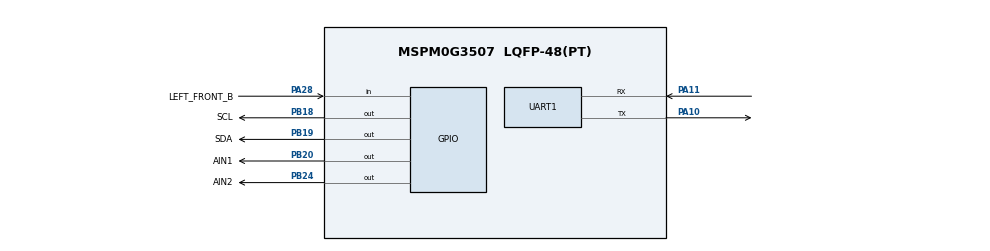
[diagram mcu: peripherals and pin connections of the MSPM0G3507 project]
/**
 * These arguments were used when this file was generated. They will be automatically applied on subsequent loads
 * via the GUI or CLI. Run CLI with '--help' for additional information on how to override these arguments.
 * @cliArgs --device "MSPM0G350X" --part "Default" --package "LQFP-48(PT)" --product "mspm0_sdk@2.10.00.04"
 * @v2CliArgs --device "MSPM0G3507" --package "LQFP-48(PT)" --product "mspm0_sdk@2.10.00.04"
 * @versions {"tool":"1.26.2+4477"}
 */

/**
 * Import the modules used in this configuration.
 */
const ADC12    = scripting.addModule("/ti/driverlib/ADC12", {}, false);
const ADC121   = ADC12.addInstance();
const CAPTURE  = scripting.addModule("/ti/driverlib/CAPTURE", {}, false);
const CAPTURE1 = CAPTURE.addInstance();
const CAPTURE2 = CAPTURE.addInstance();
const CAPTURE3 = CAPTURE.addInstance();
const CAPTURE4 = CAPTURE.addInstance();
const GPIO     = scripting.addModule("/ti/driverlib/GPIO", {}, false);
const GPIO1    = GPIO.addInstance();
const GPIO2    = GPIO.addInstance();
const GPIO3    = GPIO.addInstance();
const GPIO4    = GPIO.addInstance();
const PWM      = scripting.addModule("/ti/driverlib/PWM", {}, false);
const PWM1     = PWM.addInstance();
const SYSCTL   = scripting.addModule("/ti/driverlib/SYSCTL");
const TIMER    = scripting.addModule("/ti/driverlib/TIMER", {}, false);
const TIMER1   = TIMER.addInstance();
const UART     = scripting.addModule("/ti/driverlib/UART", {}, false);
const UART1    = UART.addInstance();

/**
 * Write custom configuration values to the imported modules.
 */
const divider9       = system.clockTree["UDIV"];
divider9.divideValue = 2;

const gate7  = system.clockTree["MFCLKGATE"];
gate7.enable = true;

const multiplier2         = system.clockTree["PLL_QDIV"];
multiplier2.multiplyValue = 4;

const mux4       = system.clockTree["EXHFMUX"];
mux4.inputSelect = "EXHFMUX_XTAL";

const mux8       = system.clockTree["HSCLKMUX"];
mux8.inputSelect = "HSCLKMUX_SYSPLL0";

const mux12       = system.clockTree["SYSPLLMUX"];
mux12.inputSelect = "zSYSPLLMUX_HFCLK";

const pinFunction4        = system.clockTree["HFXT"];
pinFunction4.inputFreq    = 40;
pinFunction4.enable       = true;
pinFunction4.HFCLKMonitor = true;
pinFunction4.HFXTStartup  = 10;

ADC121.repeatMode                        = true;
ADC121.sampClkDiv                        = "DL_ADC12_CLOCK_DIVIDE_8";
ADC121.adcMem0_name                      = "ADC_CH0";
ADC121.$name                             = "ADC_VOLTAGE";
ADC121.sampleTime0                       = "10 ms";
ADC121.enabledInterrupts                 = ["DL_ADC12_INTERRUPT_MEM0_RESULT_LOADED"];
ADC121.adcPin0Config.hideOutputInversion = scripting.forceWrite(false);
ADC121.adcPin0Config.$name               = "ti_driverlib_gpio_GPIOPinGeneric9";

const Board = scripting.addModule("/ti/driverlib/Board", {}, false);

CAPTURE1.ccIndexMulti                       = [0,1];
CAPTURE1.multi_countRep                     = "DL_TIMER_REPEAT_MODE_ENABLED";
CAPTURE1.$name                              = "CAPTURE_LEFT_FRONT";
CAPTURE1.multi_countMode                    = "DL_TIMER_COUNT_MODE_UP";
CAPTURE1.multi_cvae                         = "DL_TIMER_COUNT_AFTER_EN_ZERO";
CAPTURE1.captEdgeDetection                  = "EDGE";
CAPTURE1.multi_ch1_captEdgeDetection        = "DL_TIMER_CC_CCOND_TRIG_FALL";
CAPTURE1.interrupts                         = ["CC0_UP","CC1_UP","LOAD"];
CAPTURE1.captMode                           = "COMBINED_UP";
CAPTURE1.timerClkDiv                        = 4;
CAPTURE1.timerPeriod                        = "655.36ms";
CAPTURE1.timerClkPrescale                   = 100;
CAPTURE1.ccp0PinConfig.hideOutputInversion  = scripting.forceWrite(false);
CAPTURE1.ccp0PinConfig.onlyInternalResistor = scripting.forceWrite(false);
CAPTURE1.ccp0PinConfig.passedPeripheralType = scripting.forceWrite("Digital");
CAPTURE1.ccp0PinConfig.$name                = "ti_driverlib_gpio_GPIOPinGeneric4";

CAPTURE2.ccIndexMulti                       = [0,1];
CAPTURE2.multi_countRep                     = "DL_TIMER_REPEAT_MODE_ENABLED";
CAPTURE2.$name                              = "CAPTURE_LEFT_BACK";
CAPTURE2.multi_countMode                    = "DL_TIMER_COUNT_MODE_UP";
CAPTURE2.multi_cvae                         = "DL_TIMER_COUNT_AFTER_EN_ZERO";
CAPTURE2.multi_ch1_captEdgeDetection        = "DL_TIMER_CC_CCOND_TRIG_FALL";
CAPTURE2.captEdgeDetection                  = "EDGE";
CAPTURE2.interrupts                         = ["CC0_UP","CC1_UP","LOAD"];
CAPTURE2.captMode                           = "COMBINED_UP";
CAPTURE2.timerClkDiv                        = 4;
CAPTURE2.timerClkPrescale                   = 200;
CAPTURE2.timerPeriod                        = "655.36ms";
CAPTURE2.ccp0PinConfig.hideOutputInversion  = scripting.forceWrite(false);
CAPTURE2.ccp0PinConfig.onlyInternalResistor = scripting.forceWrite(false);
CAPTURE2.ccp0PinConfig.passedPeripheralType = scripting.forceWrite("Digital");
CAPTURE2.ccp0PinConfig.$name                = "ti_driverlib_gpio_GPIOPinGeneric7";

CAPTURE3.$name                              = "CAPTURE_RIGHT_FRONT";
CAPTURE3.ccIndexMulti                       = [0,1];
CAPTURE3.multi_countRep                     = "DL_TIMER_REPEAT_MODE_ENABLED";
CAPTURE3.multi_countMode                    = "DL_TIMER_COUNT_MODE_UP";
CAPTURE3.multi_cvae                         = "DL_TIMER_COUNT_AFTER_EN_ZERO";
CAPTURE3.multi_ch1_captEdgeDetection        = "DL_TIMER_CC_CCOND_TRIG_FALL";
CAPTURE3.captEdgeDetection                  = "EDGE";
CAPTURE3.interrupts                         = ["CC0_UP","CC1_UP","LOAD"];
CAPTURE3.captMode                           = "COMBINED_UP";
CAPTURE3.timerClkDiv                        = 4;
CAPTURE3.timerClkPrescale                   = 200;
CAPTURE3.timerPeriod                        = "655.36ms";
CAPTURE3.ccp0PinConfig.hideOutputInversion  = scripting.forceWrite(false);
CAPTURE3.ccp0PinConfig.onlyInternalResistor = scripting.forceWrite(false);
CAPTURE3.ccp0PinConfig.passedPeripheralType = scripting.forceWrite("Digital");
CAPTURE3.ccp0PinConfig.$name                = "ti_driverlib_gpio_GPIOPinGeneric8";

CAPTURE4.$name                              = "CAPTURE_RIGHT_BACK";
CAPTURE4.ccIndexMulti                       = [0,1];
CAPTURE4.multi_countRep                     = "DL_TIMER_REPEAT_MODE_ENABLED";
CAPTURE4.captEdgeDetection                  = "EDGE";
CAPTURE4.multi_countMode                    = "DL_TIMER_COUNT_MODE_UP";
CAPTURE4.multi_cvae                         = "DL_TIMER_COUNT_AFTER_EN_ZERO";
CAPTURE4.multi_ch1_captEdgeDetection        = "DL_TIMER_CC_CCOND_TRIG_FALL";
CAPTURE4.interrupts                         = ["CC0_UP","CC1_UP","LOAD"];
CAPTURE4.captMode                           = "COMBINED_UP";
CAPTURE4.timerClkDiv                        = 4;
CAPTURE4.timerClkPrescale                   = 100;
CAPTURE4.timerPeriod                        = "655.36ms";
CAPTURE4.ccp0PinConfig.hideOutputInversion  = scripting.forceWrite(false);
CAPTURE4.ccp0PinConfig.onlyInternalResistor = scripting.forceWrite(false);
CAPTURE4.ccp0PinConfig.passedPeripheralType = scripting.forceWrite("Digital");
CAPTURE4.ccp0PinConfig.$name                = "ti_driverlib_gpio_GPIOPinGeneric11";

GPIO1.$name                              = "LED";
GPIO1.port                               = "PORTA";
GPIO1.associatedPins[0].internalResistor = "PULL_DOWN";
GPIO1.associatedPins[0].assignedPin      = "14";
GPIO1.associatedPins[0].$name            = "A14";

GPIO2.$name                              = "ENCODER";
GPIO2.associatedPins.create(4);
GPIO2.associatedPins[0].direction        = "INPUT";
GPIO2.associatedPins[0].internalResistor = "PULL_UP";
GPIO2.associatedPins[0].$name            = "LEFT_FRONT_B";
GPIO2.associatedPins[0].pin.$assign      = "PA28";
GPIO2.associatedPins[1].direction        = "INPUT";
GPIO2.associatedPins[1].internalResistor = "PULL_UP";
GPIO2.associatedPins[1].$name            = "LEFT_BACK_B";
GPIO2.associatedPins[2].direction        = "INPUT";
GPIO2.associatedPins[2].internalResistor = "PULL_UP";
GPIO2.associatedPins[2].$name            = "RIGHT_FRONT_B";
GPIO2.associatedPins[3].direction        = "INPUT";
GPIO2.associatedPins[3].internalResistor = "PULL_UP";
GPIO2.associatedPins[3].$name            = "RIGHT_BACK_B";

GPIO3.$name                         = "MOTOR";
GPIO3.associatedPins.create(8);
GPIO3.associatedPins[0].$name       = "AIN1";
GPIO3.associatedPins[0].pin.$assign = "PB20";
GPIO3.associatedPins[1].$name       = "AIN2";
GPIO3.associatedPins[1].pin.$assign = "PB24";
GPIO3.associatedPins[2].$name       = "BIN1";
GPIO3.associatedPins[3].$name       = "BIN2";
GPIO3.associatedPins[4].$name       = "CIN1";
GPIO3.associatedPins[5].$name       = "CIN2";
GPIO3.associatedPins[6].$name       = "DIN1";
GPIO3.associatedPins[7].$name       = "DIN2";

GPIO4.$name                              = "Gyro";
GPIO4.associatedPins.create(2);
GPIO4.associatedPins[0].$name            = "SCL";
GPIO4.associatedPins[0].internalResistor = "PULL_UP";
GPIO4.associatedPins[0].pin.$assign      = "PB18";
GPIO4.associatedPins[1].$name            = "SDA";
GPIO4.associatedPins[1].internalResistor = "PULL_UP";
GPIO4.associatedPins[1].pin.$assign      = "PB19";

PWM1.$name                              = "PWM_MOTOR";
PWM1.timerStartTimer                    = true;
PWM1.ccIndex                            = [0,1,2,3];
PWM1.clockDivider                       = 4;
PWM1.pwmMode                            = "EDGE_ALIGN_UP";
PWM1.interrupts                         = ["LOAD_EVENT"];
PWM1.PWM_CHANNEL_0.$name                = "ti_driverlib_pwm_PWMTimerCC0";
PWM1.PWM_CHANNEL_1.$name                = "ti_driverlib_pwm_PWMTimerCC1";
PWM1.ccp0PinConfig.direction            = scripting.forceWrite("OUTPUT");
PWM1.ccp0PinConfig.hideOutputInversion  = scripting.forceWrite(false);
PWM1.ccp0PinConfig.onlyInternalResistor = scripting.forceWrite(false);
PWM1.ccp0PinConfig.passedPeripheralType = scripting.forceWrite("Digital");
PWM1.ccp0PinConfig.$name                = "ti_driverlib_gpio_GPIOPinGeneric2";
PWM1.ccp1PinConfig.direction            = scripting.forceWrite("OUTPUT");
PWM1.ccp1PinConfig.hideOutputInversion  = scripting.forceWrite(false);
PWM1.ccp1PinConfig.onlyInternalResistor = scripting.forceWrite(false);
PWM1.ccp1PinConfig.passedPeripheralType = scripting.forceWrite("Digital");
PWM1.ccp1PinConfig.$name                = "ti_driverlib_gpio_GPIOPinGeneric3";
PWM1.peripheral.$assign                 = "TIMA0";
PWM1.PWM_CHANNEL_2.$name                = "ti_driverlib_pwm_PWMTimerCC2";
PWM1.PWM_CHANNEL_3.$name                = "ti_driverlib_pwm_PWMTimerCC3";
PWM1.ccp2PinConfig.$name                = "ti_driverlib_gpio_GPIOPinGeneric5";
PWM1.ccp3PinConfig.$name                = "ti_driverlib_gpio_GPIOPinGeneric6";

SYSCTL.forceDefaultClkConfig = true;
SYSCTL.clockTreeEn           = true;
SYSCTL.useHFCLK_Manual       = true;
SYSCTL.validateClkStatus     = true;

TIMER1.$name             = "TIMER_0";
TIMER1.interruptPriority = "3";
TIMER1.timerClkDiv       = 8;
TIMER1.timerClkPrescale  = 10;
TIMER1.timerPeriod       = "65.536ms";
TIMER1.timerMode         = "PERIODIC_UP";
TIMER1.interrupts        = ["LOAD"];

UART1.enabledInterrupts                = ["RX"];
UART1.interruptPriority                = "3";
UART1.targetBaudRate                   = 115200;
UART1.$name                            = "UART_0_DEBUG";
UART1.peripheral.$assign               = "UART0";
UART1.peripheral.rxPin.$assign         = "PA11";
UART1.peripheral.txPin.$assign         = "PA10";
UART1.txPinConfig.direction            = scripting.forceWrite("OUTPUT");
UART1.txPinConfig.hideOutputInversion  = scripting.forceWrite(false);
UART1.txPinConfig.onlyInternalResistor = scripting.forceWrite(false);
UART1.txPinConfig.passedPeripheralType = scripting.forceWrite("Digital");
UART1.txPinConfig.$name                = "ti_driverlib_gpio_GPIOPinGeneric0";
UART1.rxPinConfig.hideOutputInversion  = scripting.forceWrite(false);
UART1.rxPinConfig.onlyInternalResistor = scripting.forceWrite(false);
UART1.rxPinConfig.passedPeripheralType = scripting.forceWrite("Digital");
UART1.rxPinConfig.$name                = "ti_driverlib_gpio_GPIOPinGeneric1";

const ProjectConfig              = scripting.addModule("/ti/project_config/ProjectConfig", {}, false);
ProjectConfig.migrationCondition = true;

/**
 * Pinmux solution for unlocked pins/peripherals. This ensures that minor changes to the automatic solver in a future
 * version of the tool will not impact the pinmux you originally saw.  These lines can be completely deleted in order to
 * re-solve from scratch.
 */
pinFunction4.peripheral.$suggestSolution           = "SYSCTL";
pinFunction4.peripheral.hfxInPin.$suggestSolution  = "PA5";
pinFunction4.peripheral.hfxOutPin.$suggestSolution = "PA6";
ADC121.peripheral.$suggestSolution                 = "ADC0";
ADC121.peripheral.adcPin0.$suggestSolution         = "PA27";
Board.peripheral.$suggestSolution                  = "DEBUGSS";
Board.peripheral.swclkPin.$suggestSolution         = "PA20";
Board.peripheral.swdioPin.$suggestSolution         = "PA19";
CAPTURE1.peripheral.$suggestSolution               = "TIMG8";
CAPTURE1.peripheral.ccp0Pin.$suggestSolution       = "PA26";
CAPTURE2.peripheral.$suggestSolution               = "TIMG7";
CAPTURE2.peripheral.ccp0Pin.$suggestSolution       = "PA17";
CAPTURE3.peripheral.$suggestSolution               = "TIMG6";
CAPTURE3.peripheral.ccp0Pin.$suggestSolution       = "PA21";
CAPTURE4.peripheral.$suggestSolution               = "TIMG0";
CAPTURE4.peripheral.ccp0Pin.$suggestSolution       = "PA23";
GPIO1.associatedPins[0].pin.$suggestSolution       = "PA14";
GPIO2.associatedPins[1].pin.$suggestSolution       = "PA3";
GPIO2.associatedPins[2].pin.$suggestSolution       = "PA2";
GPIO2.associatedPins[3].pin.$suggestSolution       = "PA31";
GPIO3.associatedPins[2].pin.$suggestSolution       = "PA4";
GPIO3.associatedPins[3].pin.$suggestSolution       = "PA7";
GPIO3.associatedPins[4].pin.$suggestSolution       = "PB2";
GPIO3.associatedPins[5].pin.$suggestSolution       = "PB3";
GPIO3.associatedPins[6].pin.$suggestSolution       = "PA8";
GPIO3.associatedPins[7].pin.$suggestSolution       = "PA9";
PWM1.peripheral.ccp0Pin.$suggestSolution           = "PA0";
PWM1.peripheral.ccp1Pin.$suggestSolution           = "PA1";
PWM1.peripheral.ccp2Pin.$suggestSolution           = "PA15";
PWM1.peripheral.ccp3Pin.$suggestSolution           = "PA12";
TIMER1.peripheral.$suggestSolution                 = "TIMA1";
